# STM32H7P4xx register map
File version: 1.0
Registers are 32-bit, read-write, reset 0x0 unless marked. A register's access mark holds for its fields unless they carry their own. Offsets are from the block's base; [hi:lo] are bit positions; {n}, {i} and the like mark numbered series; 'fields as' and 'values as' point back to an identical list.

## RTC — Real-time clock (RTC)
Base 0x58004000
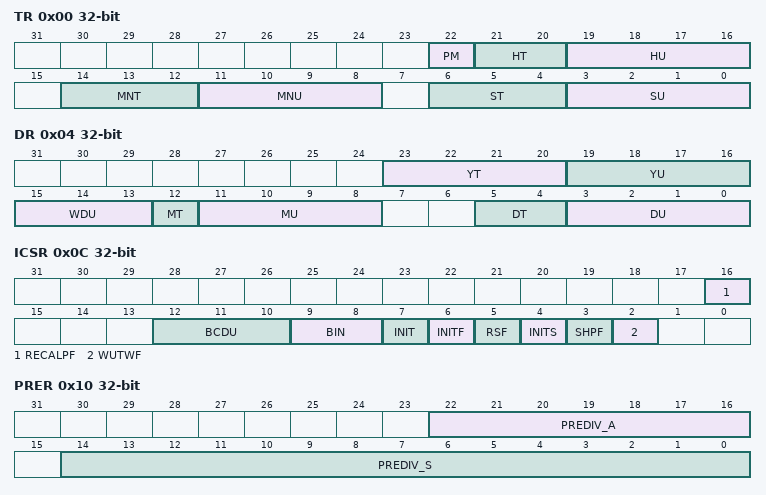
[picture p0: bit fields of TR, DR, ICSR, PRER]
0x00 TR — RTC time register
  [22] PM — AM/PM notation
  [21:20] HT — Hour tens in BCD format
  [19:16] HU — Hour units in BCD format
  [14:12] MNT — Minute tens in BCD format
  [11:8] MNU — Minute units in BCD format
  [6:4] ST — Second tens in BCD format
  [3:0] SU — Second units in BCD format
0x04 DR — RTC date register
  [23:20] YT — Year tens in BCD format
  [19:16] YU — Year units in BCD format
  [15:13] WDU — Week day units
  [12] MT — Month tens in BCD format
  [11:8] MU — Month units in BCD format
  [5:4] DT — Date tens in BCD format
  [3:0] DU — Date units in BCD format
0x08 SSR ro — RTC subsecond register
  [31:0] SS — Synchronous binary counter
0x0C ICSR — RTC initialization control and status register
  [16] RECALPF — Recalibration pending Flag
  [12:10] BCDU — BCD update (BIN = 10 or 11)
  [9:8] BIN — Binary mode
  [7] INIT — Initialization mode
  [6] INITF — Initialization flag
  [5] RSF — Registers synchronization flag
  [4] INITS — Initialization status flag
  [3] SHPF — Shift operation pending
  [2] WUTWF — Wake-up timer write flag
0x10 PRER — RTC prescaler register
  [22:16] PREDIV_A — Asynchronous prescaler factor
  [14:0] PREDIV_S — Synchronous prescaler factor
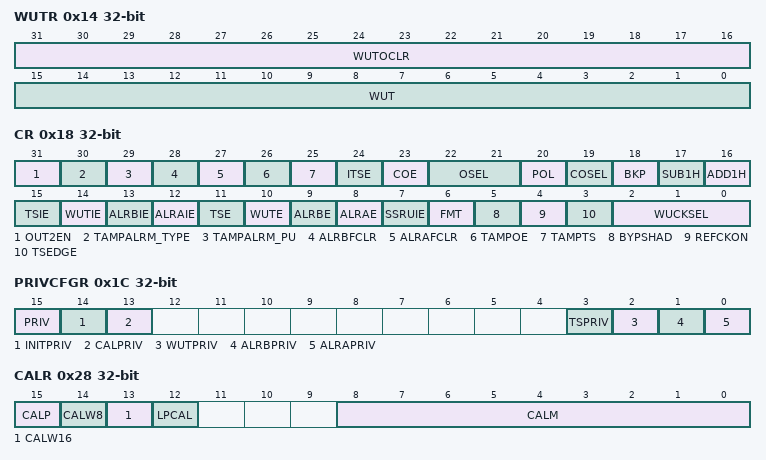
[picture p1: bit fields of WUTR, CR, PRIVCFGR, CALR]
0x14 WUTR — RTC wake-up timer register
  [31:16] WUTOCLR — Wake-up auto-reload output clear value
  [15:0] WUT — Wake-up auto-reload value bits
0x18 CR — RTC control register
  [31] OUT2EN — RTC_OUT2 output enable
  [30] TAMPALRM_TYPE — TAMPALRM output type
  [29] TAMPALRM_PU — TAMPALRM pull-up enable
  [28] ALRBFCLR — Alarm B flag automatic clear
  [27] ALRAFCLR — Alarm A flag automatic clear
  [26] TAMPOE — Tamper detection output enable on TAMPALRM
  [25] TAMPTS — Activate timestamp on tamper detection event
  [24] ITSE — timestamp on internal event enable
  [23] COE — Calibration output enable
  [22:21] OSEL — Output selection
  [20] POL — Output polarity
  [19] COSEL — Calibration output selection
  [18] BKP — Backup
  [17] SUB1H — Subtract 1 hour (winter time change)
  [16] ADD1H — Add 1 hour (summer time change)
  [15] TSIE — Timestamp interrupt enable
  [14] WUTIE — Wake-up timer interrupt enable
  [13] ALRBIE — Alarm B interrupt enable
  [12] ALRAIE — Alarm A interrupt enable
  [11] TSE — timestamp enable
  [10] WUTE — Wake-up timer enable
  [9] ALRBE — Alarm B enable
  [8] ALRAE — Alarm A enable
  [7] SSRUIE — SSR underflow interrupt enable
  [6] FMT — Hour format
  [5] BYPSHAD — Bypass the shadow registers
  [4] REFCKON — RTC_REFIN reference clock detection enable (50 or 60 Hz)
  [3] TSEDGE — Timestamp event active edge
  [2:0] WUCKSEL — ck_wut wake-up clock selection
0x1C PRIVCFGR — RTC privilege mode control register
  [15] PRIV — RTC privilege protection
  [14] INITPRIV — Initialization privilege protection
  [13] CALPRIV — Shift register, Delight saving, calibration and reference clock privilege protection
  [3] TSPRIV — Timestamp privilege protection
  [2] WUTPRIV — Wake-up timer privilege protection
  [1] ALRBPRIV — Alarm B privilege protection
  [0] ALRAPRIV — Alarm A and SSR underflow privilege protection
0x24 WPR — RTC write protection register
  [7:0] KEY — Write protection key
0x28 CALR — RTC calibration register
  [15] CALP — Increase frequency of RTC by 488.5 ppm
  [14] CALW8 — Use an 8-second calibration cycle period
  [13] CALW16 — Use a 16-second calibration cycle period
  [12] LPCAL — RTC low-power mode
  [8:0] CALM — Calibration minus
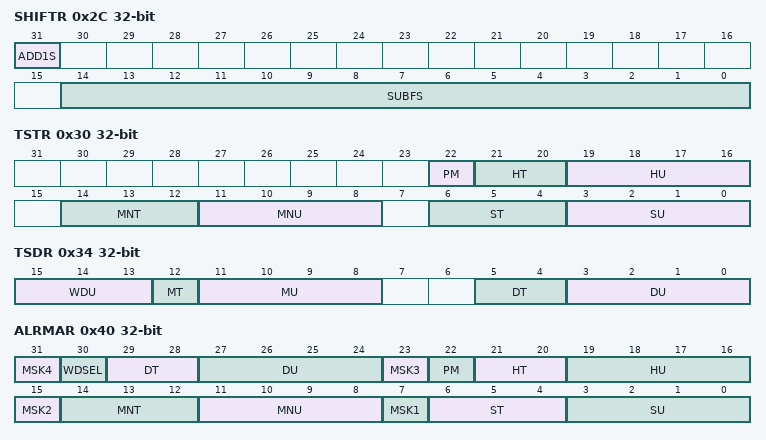
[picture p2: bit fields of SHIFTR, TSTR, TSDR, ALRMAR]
0x2C SHIFTR — RTC shift control register
  [31] ADD1S — Add one second
  [14:0] SUBFS — Subtract a fraction of a second
0x30 TSTR ro — RTC timestamp time register
  fields as TR
0x34 TSDR ro — RTC timestamp date register
  [15:13] WDU — Week day units
  [12] MT — Month tens in BCD format
  [11:8] MU — Month units in BCD format
  [5:4] DT — Date tens in BCD format
  [3:0] DU — Date units in BCD format
0x38 TSSSR ro — RTC timestamp subsecond register
  [31:0] SS — Subsecond value/synchronous binary counter values
0x40 ALRMAR — RTC alarm A register
  [31] MSK4 — Alarm A date mask
  [30] WDSEL — Week day selection
  [29:28] DT — Date tens in BCD format
  [27:24] DU — Date units or day in BCD format
  [23] MSK3 — Alarm A hours mask
  [22] PM — AM/PM notation
  [21:20] HT — Hour tens in BCD format
  [19:16] HU — Hour units in BCD format
  [15] MSK2 — Alarm A minutes mask
  [14:12] MNT — Minute tens in BCD format
  [11:8] MNU — Minute units in BCD format
  [7] MSK1 — Alarm A seconds mask
  [6:4] ST — Second tens in BCD format
  [3:0] SU — Second units in BCD format
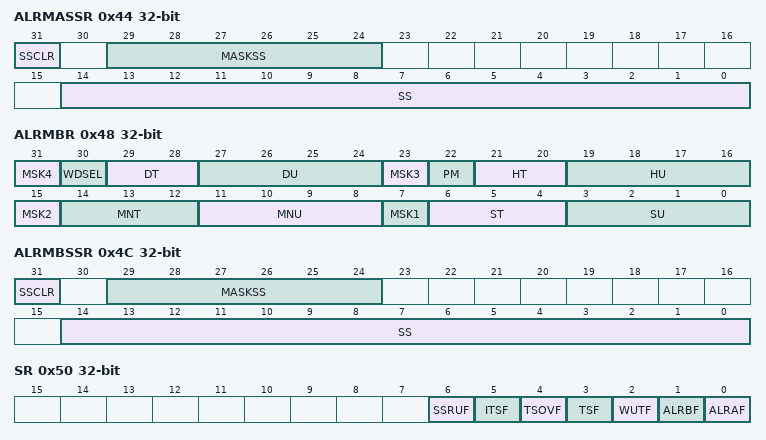
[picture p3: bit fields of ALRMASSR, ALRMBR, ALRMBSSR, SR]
0x44 ALRMASSR — RTC alarm A subsecond register
  [31] SSCLR — Clear synchronous counter on alarm (Binary mode only)
  [29:24] MASKSS — Mask the most-significant bits starting at this bit
  [14:0] SS — Subseconds value
0x48 ALRMBR — RTC alarm B register
  [31] MSK4 — Alarm B date mask
  [30] WDSEL — Week day selection
  [29:28] DT — Date tens in BCD format
  [27:24] DU — Date units or day in BCD format
  [23] MSK3 — Alarm B hours mask
  [22] PM — AM/PM notation
  [21:20] HT — Hour tens in BCD format
  [19:16] HU — Hour units in BCD format
  [15] MSK2 — Alarm B minutes mask
  [14:12] MNT — Minute tens in BCD format
  [11:8] MNU — Minute units in BCD format
  [7] MSK1 — Alarm B seconds mask
  [6:4] ST — Second tens in BCD format
  [3:0] SU — Second units in BCD format
0x4C ALRMBSSR — RTC alarm B subsecond register
  fields as ALRMASSR
0x50 SR ro — RTC status register
  [6] SSRUF — SSR underflow flag
  [5] ITSF — Internal timestamp flag
  [4] TSOVF — Timestamp overflow flag
  [3] TSF — Timestamp flag
  [2] WUTF — Wake-up timer flag
  [1] ALRBF — Alarm B flag
  [0] ALRAF — Alarm A flag
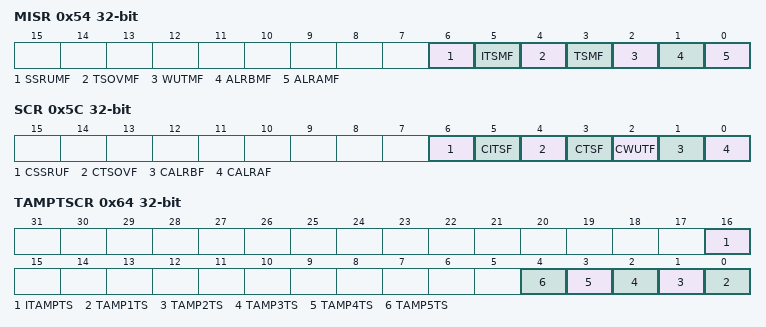
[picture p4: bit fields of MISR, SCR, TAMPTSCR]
0x54 MISR ro — RTC masked interrupt status register
  [6] SSRUMF — SSR underflow masked flag
  [5] ITSMF — Internal timestamp masked flag
  [4] TSOVMF — Timestamp overflow masked flag
  [3] TSMF — Timestamp masked flag
  [2] WUTMF — Wake-up timer masked flag
  [1] ALRBMF — Alarm B masked flag
  [0] ALRAMF — Alarm A masked flag
0x5C SCR — RTC status clear register
  [6] CSSRUF — Clear SSR underflow flag
  [5] CITSF — Clear internal timestamp flag
  [4] CTSOVF — Clear timestamp overflow flag
  [3] CTSF — Clear timestamp flag
  [2] CWUTF — Clear wake-up timer flag
  [1] CALRBF — Clear alarm B flag
  [0] CALRAF — Clear alarm A flag
0x64 TAMPTSCR — RTC timestamp on tamper control register
  [16] ITAMPTS — Timestamp on internal tamper event
  [n-1] TAMP{n}TS (n=1..5) — Timestamp on external tamper TAMP{n} event
0x68 TSIDR ro — RTC timestamp status register
  [5:0] TSID — Timestamp flag source identification
0x70 ALRABINR — RTC alarm A binary mode register
  [31:0] SS — Synchronous counter alarm value in Binary mode
0x74 ALRBBINR — RTC alarm B binary mode register
  [31:0] SS — Synchronous counter alarm value in Binary mode
